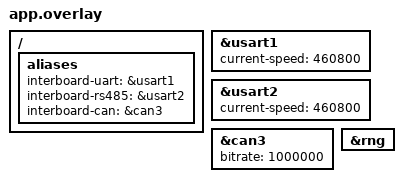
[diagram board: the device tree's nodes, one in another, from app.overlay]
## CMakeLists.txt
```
cmake_minimum_required(VERSION 3.20.0)
find_package(Zephyr REQUIRED HINTS $ENV{ZEPHYR_BASE})
project(interboard_bench)
target_sources(app PRIVATE src/main.cpp)
```

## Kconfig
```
mainmenu "Interboard UART / RS485 / CAN bench"
source "Kconfig.zephyr"
config BENCH_CHASSIS_ROLE
    bool "Use the chassis peer role"
    default n

choice BENCH_TRANSPORT
    prompt "Interboard transport selected at initialization"
    default BENCH_TRANSPORT_UART
config BENCH_TRANSPORT_UART
    bool "UART"
config BENCH_TRANSPORT_RS485
    bool "Two-wire RS485"
config BENCH_TRANSPORT_CAN
    bool "Classic CAN on dedicated CAN3"
endchoice

rsource "../../robotics/common/sample_control.Kconfig"
```

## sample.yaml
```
sample:
  name: SkyWalker interboard on-board bench
  description: Standalone DM MC02 hardware exercise; requires the documented wiring
common:
  tags: [skywalker, hardware]
  platform_allow: [dm_mc02/stm32h723xx]
  build_only: true
tests:
  sample.skywalker.communication.interboard: {}
  sample.skywalker.communication.interboard.version_mismatch:
    extra_args: EXTRA_CONF_FILE=version_mismatch.conf
```

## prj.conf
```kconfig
CONFIG_CPP=y
CONFIG_STD_CPP20=y
CONFIG_REQUIRES_FULL_LIBCPP=y
CONFIG_MAIN_STACK_SIZE=8192
CONFIG_LOG=y
CONFIG_CBPRINTF_FP_SUPPORT=y
CONFIG_SERIAL=y
CONFIG_UART_ASYNC_API=y
CONFIG_SKYWALKER_LIB_COMMUNICATION=y
CONFIG_SKYWALKER_UART_TRANSPORT=y
CONFIG_ENTROPY_GENERATOR=y
CONFIG_CAN=y
CONFIG_SKYWALKER_INTERBOARD_ENDPOINT=y
CONFIG_SKYWALKER_INTERBOARD_RS485=y
CONFIG_SKYWALKER_INTERBOARD_CAN=y
```

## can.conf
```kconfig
CONFIG_BENCH_TRANSPORT_CAN=y
```

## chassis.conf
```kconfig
CONFIG_BENCH_CHASSIS_ROLE=y
```

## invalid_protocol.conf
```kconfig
CONFIG_SAMPLE_DIAGNOSTIC_SCENARIO=8
```

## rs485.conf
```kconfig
CONFIG_BENCH_TRANSPORT_RS485=y
```

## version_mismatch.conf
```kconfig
CONFIG_BENCH_BIG_YAW_CONTRACT_VERSION=1
```

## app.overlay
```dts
/* Connect board A PA9 -> board B PA10, board B PA9 -> board A PA10, and GND. */
/ {
    aliases {
        interboard-uart = &usart1;
        interboard-rs485 = &usart2;
        interboard-can = &can3;
    };
};

&usart1 {
    current-speed = <460800>;
};

/* MC02 hardware DE PD4, TX PD5, RX PD6; DMA uses the global board map. */
&usart2 {
    current-speed = <460800>;
};

&can3 {
    bitrate = <1000000>;
};

&rng {
    status = "okay";
};
```

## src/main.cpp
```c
#include <zephyr/kernel.h>
#include <zephyr/logging/log.h>
#include <zephyr/drivers/uart.h>
#include <communication/interboard/interboard_endpoint.hpp>
#include "board_config.hpp"
LOG_MODULE_REGISTER(interboard_bench, LOG_LEVEL_INF);

int main() {
    using namespace skywalker::communication;
    using namespace skywalker::robotics;
    static AsyncUart::DmaBuffers dma_buffers __nocache;
    static ConfiguredInterBoardTransport transport(bench::transport, &dma_buffers);
    static InterBoardEndpoint link(transport, [] {
        InterBoardEndpoint::Config c{bench::role}; c.enable_big_yaw = true;
        c.big_yaw_contract_version = CONFIG_BENCH_BIG_YAW_CONTRACT_VERSION; return c;
    }());
    const device *console = DEVICE_DT_GET(DT_CHOSEN(zephyr_console));
    LOG_INF("transport=%u role=%u; p: pause command; s: pause execution status; g: wheel generation; b: big-Yaw generation",
            unsigned(transport.kind()), unsigned(bench::role));
    ChassisCommand command{};
    RunStatus status{};
    status.ready = true;
    status.generation = 1;
    std::uint64_t next_command = 0, next_log = 0;
    std::uint32_t sequence = 0, status_sequence = 0;
    BigYawRequest big_yaw_request{};
    BigYawFeedback big_yaw_feedback{};
    big_yaw_feedback.resume_generation = 1;
    bool produce = true, produce_status = true;
    for (;;) {
        const auto now = static_cast<std::uint64_t>(k_uptime_get());
        unsigned char key = 0;
        if (uart_poll_in(console, &key) == 0) {
            if (key == 'p') produce = !produce;
            if (key == 's') produce_status = !produce_status;
            if (key == 'g') ++status.generation;
            if (key == 'b') ++big_yaw_feedback.resume_generation;
        }
        if (bench::role == BoardRole::GimbalController && produce && now >= next_command) {
            next_command = now + 10;
            command.mode = ChassisMode::BodyVelocity;
            command.source = ControlSource::Remote;
            command.vx_m_s = bench::target_vx_m_s;
            command.stamp = {now, ++sequence, true};
            link.submit(command);
            big_yaw_request.mode = BigYawMode::FollowCenter;
            big_yaw_request.target_rate_rad_s = 0.1f;
            big_yaw_request.source_sequence = sequence; big_yaw_request.stamp = command.stamp;
            big_yaw_request.permission = {true, true, command.stamp};
            link.submitBigYaw(big_yaw_request);
        }
        const auto previous = link.snapshot();
        const bool fresh = isFresh(previous.control.command.stamp, now, 100);
        const bool context = previous.local_boot_id &&
            previous.control.receiver_boot_id == previous.local_boot_id &&
            previous.control.resume_generation == status.generation;
        status.state = previous.online && fresh && context ? RunState::Active : RunState::Recovering;
        status.reason = previous.online ? WaitReason::Command : WaitReason::Transport;
        if (status.state == RunState::Active) status.reason = WaitReason::None;
        status.last_command_sequence = previous.control.command.stamp.sequence;
        if (produce_status) {
            status.stamp = {now, ++status_sequence, true};
            link.setStatus(status);
            // A no-output execution simulation with a distinct recovery context.
            const auto &r = previous.big_yaw_request;
            const bool big_yaw_active = previous.big_yaw_compatible &&
                forwardedFresh(r.stamp, r.source_age_ms, now, 100) &&
                forwardedFresh(r.stamp, r.command_age_ms, now, 100) &&
                r.receiver_boot_id == previous.local_boot_id &&
                r.resume_generation == big_yaw_feedback.resume_generation &&
                r.mode == BigYawMode::FollowCenter && r.permission.valid && r.permission.enabled &&
                forwardedFresh(r.permission.stamp, r.permission_age_ms, now, 300);
            big_yaw_feedback.execution_state = big_yaw_active ? ExecutionState::Active : ExecutionState::Ready;
            big_yaw_feedback.ready = true; big_yaw_feedback.armed = big_yaw_active; big_yaw_feedback.valid = true;
            big_yaw_feedback.last_command_sequence = r.stamp.sequence;
            big_yaw_feedback.actual_rate_rad_s = 0; // This protocol bench has no motor.
            big_yaw_feedback.stamp = status.stamp;
            link.setBigYawFeedback(big_yaw_feedback);
        }
        link.poll(now);
        if (now >= next_log) {
            next_log = now + 200;
            const auto rx = link.snapshot();
            LOG_INF("transport=%u error=%d peer_online=%d peer_boot=%llx peer_gen=%u local_gen=%u cmd_seq=%u cmd_fresh=%d peer_ready=%d status_producing=%d CRC=%u",
                    unsigned(rx.transport), rx.error, rx.online, rx.peer.sender_boot_id,
                    rx.peer.resume_generation, status.generation, rx.control.command.stamp.sequence,
                    isFresh(rx.control.command.stamp, now, 100), rx.peer.ready, produce_status,
                    rx.parser_stats.crc_errors);
            LOG_INF("bigYaw compatible=%d local_gen=%u peer_gen=%u req_source=%u req_age=%u peer_ready=%d peer_valid=%d advertised_contract=%u",
                    rx.big_yaw_compatible, big_yaw_feedback.resume_generation,
                    rx.big_yaw_feedback.resume_generation, rx.big_yaw_request.source_sequence,
                    rx.big_yaw_request.source_age_ms, rx.big_yaw_feedback.ready,
                    rx.big_yaw_feedback.valid, CONFIG_BENCH_BIG_YAW_CONTRACT_VERSION);
        }
        k_sleep(K_MSEC(1));
    }
}
```

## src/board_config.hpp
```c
#pragma once
#include <zephyr/device.h>
#include <robotics/messages/interboard.hpp>
#include <communication/interboard/configured_interboard_transport.hpp>
namespace bench {
inline const device *uart = DEVICE_DT_GET(DT_ALIAS(interboard_uart));
#ifdef CONFIG_BENCH_CHASSIS_ROLE
inline constexpr auto role = skywalker::robotics::BoardRole::ChassisController;
#else
inline constexpr auto role = skywalker::robotics::BoardRole::GimbalController;
#endif
inline constexpr float target_vx_m_s = 0.2f; // Sent as a semantic command; this sample owns no motors.
inline const skywalker::communication::ConfiguredInterBoardTransport::Config transport = [] {
    using namespace skywalker::communication;
    ConfiguredInterBoardTransport::Config c{};
#if defined(CONFIG_BENCH_TRANSPORT_RS485)
    c.kind = InterBoardTransportKind::Rs485;
#elif defined(CONFIG_BENCH_TRANSPORT_CAN)
    c.kind = InterBoardTransportKind::Can;
#endif
    c.uart = uart;
    c.rs485.uart = DEVICE_DT_GET(DT_ALIAS(interboard_rs485));
    const bool coordinator = role == skywalker::robotics::BoardRole::GimbalController;
    c.rs485.role = coordinator ? Rs485InterBoardTransport::Role::Coordinator
                               : Rs485InterBoardTransport::Role::Responder;
    c.can.can = DEVICE_DT_GET(DT_ALIAS(interboard_can));
    c.can.tx_id = coordinator ? 0x600 : 0x601;
    c.can.rx_id = coordinator ? 0x601 : 0x600;
    return c;
}();
}
```
